# STM32H7S register map
File version: 1.4
CPU: CM7 r0p1, little endian, MPU, FPU, 4 interrupt priority bits
Registers are 32-bit, read-write, reset 0x0 unless marked. A register's access mark holds for its fields unless they carry their own. Offsets are from the block's base; [hi:lo] are bit positions.

## ADC12_common — master and slave ADC common
Base 0x40022300
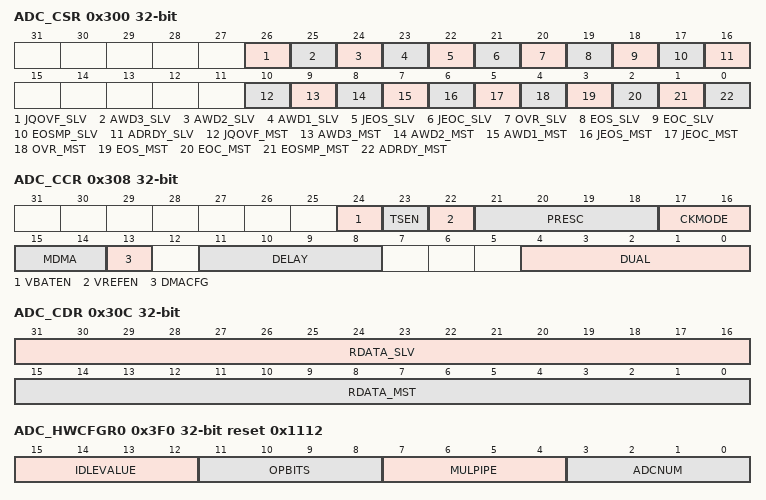
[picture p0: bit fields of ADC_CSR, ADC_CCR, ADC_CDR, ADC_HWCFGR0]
0x300 ADC_CSR ro — ADC common status register
  [26] JQOVF_SLV — Injected Context Queue Overflow flag of the slave ADC This bit is a copy of the JQOVF bit in the corresponding ADC_ISR register.
  [25] AWD3_SLV — Analog watchdog 3 flag of the slave ADC This bit is a copy of the AWD3 bit in the corresponding ADC_ISR register.
  [24] AWD2_SLV — Analog watchdog 2 flag of the slave ADC This bit is a copy of the AWD2 bit in the corresponding ADC_ISR register.
  [23] AWD1_SLV — Analog watchdog 1 flag of the slave ADC This bit is a copy of the AWD1 bit in the corresponding ADC_ISR register.
  [22] JEOS_SLV — End of injected sequence flag of the slave ADC This bit is a copy of the JEOS bit in the corresponding ADC_ISR register.
  [21] JEOC_SLV — End of injected conversion flag of the slave ADC This bit is a copy of the JEOC bit in the corresponding ADC_ISR register.
  [20] OVR_SLV — Overrun flag of the slave ADC This bit is a copy of the OVR bit in the corresponding ADC_ISR register.
  [19] EOS_SLV — End of regular sequence flag of the slave ADC. This bit is a copy of the EOS bit in the corresponding ADC_ISR register.
  [18] EOC_SLV — End of regular conversion of the slave ADC This bit is a copy of the EOC bit in the corresponding ADC_ISR register.
  [17] EOSMP_SLV — End of Sampling phase flag of the slave ADC This bit is a copy of the EOSMP2 bit in the corresponding ADC_ISR register.
  [16] ADRDY_SLV — Slave ADC ready This bit is a copy of the ADRDY bit in the corresponding ADC_ISR register.
  [10] JQOVF_MST — Injected Context Queue Overflow flag of the master ADC This bit is a copy of the JQOVF bit in the corresponding ADC_ISR register.
  [9] AWD3_MST — Analog watchdog 3 flag of the master ADC This bit is a copy of the AWD3 bit in the corresponding ADC_ISR register.
  [8] AWD2_MST — Analog watchdog 2 flag of the master ADC This bit is a copy of the AWD2 bit in the corresponding ADC_ISR register.
  [7] AWD1_MST — Analog watchdog 1 flag of the master ADC This bit is a copy of the AWD1 bit in the corresponding ADC_ISR register.
  [6] JEOS_MST — End of injected sequence flag of the master ADC This bit is a copy of the JEOS bit in the corresponding ADC_ISR register.
  [5] JEOC_MST — End of injected conversion flag of the master ADC This bit is a copy of the JEOC bit in the corresponding ADC_ISR register.
  [4] OVR_MST — Overrun flag of the master ADC This bit is a copy of the OVR bit in the corresponding ADC_ISR register.
  [3] EOS_MST — End of regular sequence flag of the master ADC This bit is a copy of the EOS bit in the corresponding ADC_ISR register.
  [2] EOC_MST — End of regular conversion of the master ADC This bit is a copy of the EOC bit in the corresponding ADC_ISR register.
  [1] EOSMP_MST — End of Sampling phase flag of the master ADC This bit is a copy of the EOSMP bit in the corresponding ADC_ISR register.
  [0] ADRDY_MST — Master ADC ready This bit is a copy of the ADRDY bit in the corresponding ADC_ISR register.
0x308 ADC_CCR — ADC common control register
  [24] VBATEN — VBAT enable This bit is set and cleared by software to control.
    0=V<sub>BAT</sub> channel disabled; 1=V<sub>BAT</sub> channel enabled
  [23] TSEN — V<sub>SENSE</sub> enable This bit is set and cleared by software to control V<sub>SENSE</sub>.
    0=Temperature sensor channel disabled; 1=Temperature sensor channel enabled
  [22] VREFEN — V<sub>REFINT</sub> enable This bit is set and cleared by software to enable/disable the V<sub>REFINT</sub> channel.
    0=V<sub>REFINT</sub> channel disabled; 1=V<sub>REFINT</sub> channel enabled
  [21:18] PRESC — ADC prescaler These bits are set and cleared by software to select the frequency of the clock to the ADC. The clock is common for all the ADCs. other: reserved Note: The software is allowed to write these bits only when the ADC is disabled (ADCAL = 0, JADSTART = 0, ADSTART = 0, ADSTP = 0, ADDIS = 0 and ADEN = 0). The ADC prescaler value is applied only when CKMODE[1:0] = 0b00.
    0=input ADC clock not divided; 1=input ADC clock divided by 2; 2=input ADC clock divided by 4; 3=input ADC clock divided by 6; 4=input ADC clock divided by 8; 5=input ADC clock divided by 10; 6=input ADC clock divided by 12; 7=input ADC clock divided by 16; 8=input ADC clock divided by 32; 9=input ADC clock divided by 64; 10=input ADC clock divided by 128; 11=input ADC clock divided by 256
  [17:16] CKMODE — ADC clock mode These bits are set and cleared by software to define the ADC clock scheme (which is common to both master and slave ADCs): In all synchronous clock modes, there is no jitter in the delay from a timer trigger to the start of a conversion. Note: The software is allowed to write these bits only when the ADCs are disabled (ADCAL = 0, JADSTART = 0, ADSTART = 0, ADSTP = 0, ADDIS = 0 and ADEN = 0).
    0=adc_ker_ck (x = 1/2) (Asynchronous clock mode), generated at product level (refer to Section 6: Reset and clock control (RCC)); 1=adc_hclk/1 (Synchronous clock mode). This configuration must be enabled only if the AHB clock prescaler is set to 1 (HPRE[3:0] = 0XXX in RCC_CFGR register) and if the system clock has a 50% duty cycle.; 2=adc_hclk/2 (Synchronous clock mode); 3=adc_hclk/4 (Synchronous clock mode)
  [15:14] MDMA — Direct memory access mode for dual ADC mode This bitfield is set and cleared by software. Refer to the DMA controller section for more details. Note: The software is allowed to write these bits only when ADSTART = 0 (which ensures that no regular conversion is ongoing).
    0=MDMA mode disabled; 1=FIELD Reserved; 2=MDMA mode enabled for 12 and 10-bit resolution; 3=MDMA mode enabled for 8 and 6-bit resolution
  [13] DMACFG — DMA configuration (for dual ADC mode) This bit is set and cleared by software to select between two DMA modes of operation and is effective only when DMAEN = 1. For more details, refer to Section : Managing conversions using the DMA Note: The software is allowed to write these bits only when ADSTART = 0 (which ensures that no regular conversion is ongoing).
    0=DMA One Shot mode selected; 1=DMA Circular mode selected
  [11:8] DELAY — Delay between 2 sampling phases These bits are set and cleared by software. These bits are used in dual interleaved modes. Refer to Table 198 for the value of ADC resolution versus DELAY bits values. Note: The software is allowed to write these bits only when the ADCs are disabled (ADCAL = 0, JADSTART = 0, ADSTART = 0, ADSTP = 0, ADDIS = 0 and ADEN = 0).
  [4:0] DUAL — Dual ADC mode selection These bits are written by software to select the operating mode. 00000 corresponds to Independent mode. Values 00001 to 01001 correspond to Dual mode, master and slave ADCs working together. Others: Reserved, must not be used Note: The software is allowed to write these bits only when the ADCs are disabled (ADCAL = 0, JADSTART = 0, ADSTART = 0, ADSTP = 0, ADDIS = 0 and ADEN = 0).
    0=Independent mode; 1=Combined regular simultaneous + injected simultaneous mode; 2=Combined regular simultaneous + alternate trigger mode; 3=Combined Interleaved mode + injected simultaneous mode; 4=FIELD Reserved; 5=Injected simultaneous mode only; 6=Regular simultaneous mode only; 7=Interleaved mode only; 9=Alternate trigger mode only
0x30C ADC_CDR ro — ADC common regular data register for dual mode
  [31:16] RDATA_SLV — Regular data of the slave ADC In dual mode, these bits contain the regular data of the slave ADC. Refer to Section 25.4.31: Dual ADC modes. The data alignment is applied as described in Section : Data register, data alignment and offset (ADC_DR, OFFSET, OFFSET_CH, ALIGN))
  [15:0] RDATA_MST — Regular data of the master ADC. In dual mode, these bits contain the regular data of the master ADC. Refer to Section 25.4.31: Dual ADC modes. The data alignment is applied as described in Section : Data register, data alignment and offset (ADC_DR, OFFSET, OFFSET_CH, ALIGN)) In MDMA = 0b11 mode, bits 15:8 contains SLV_ADC_DR[7:0], bits 7:0 contains MST_ADC_DR[7:0].
0x3F0 ADC_HWCFGR0 ro reset 0x1112 — ADC hardware configuration register
  [15:12] IDLEVALUE — Idle value for non-selected channels
    0=Dummy channel selection is 0x13; 1=Dummy channel selection is 0x1F
  [11:8] OPBITS — Number of option bits
    0=No option register implemented; 1=1 option bit implemented in the ADC option register (ADC_OR) at address offset 0xC8
  [7:4] MULPIPE — Number of pipeline stages
    1=One-stage pipeline
  [3:0] ADCNUM — Number of ADCs implemented
    1=One ADC instance implemented; 2=Two ADC instances implemented; 3=Three ADCs instances implemented
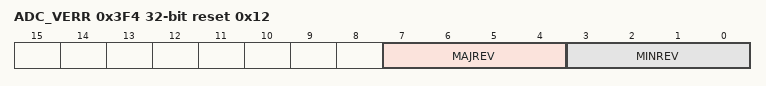
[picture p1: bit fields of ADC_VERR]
0x3F4 ADC_VERR ro reset 0x12 — ADC version register
  [7:4] MAJREV — Major revision These bits returns the ADC IP major revision
    1=Major revision = 1.X
  [3:0] MINREV — Minor revision These bits returns the ADC IP minor revision
    1=Major revision = X.1
0x3F8 ADC_IPDR ro reset 0x110006 — ADC identification register
  [31:0] ID — Peripheral identifier These bits returns the ADC identifier. ID[31:0] = 0x0011 0006: c7amba_aditf5_90_v1
0x3FC ADC_SIDR ro reset 0xA3C5DD01 — ADC size identification register
  [31:0] SID — Size Identification SID[31:8]: fixed code that characterizes the ADC_SIDR register. This field is always read at 0xA3C5DD. SID[7:0]: read-only numeric field that returns the address offset (in Kbytes) of the identification registers from the IP base address:
    1=1 Kbytes address offset; 2=2 Kbytes address offset; 4=4 Kbytes address offset; 8=8 Kbytes address offset
